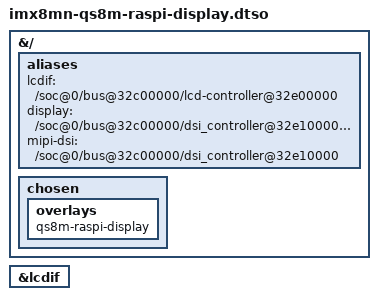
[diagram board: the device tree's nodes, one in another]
// SPDX-License-Identifier: (GPL-2.0 OR MIT)
/*
 * Copyright 2022 Lothar Waßmann <LW@KARO-electronics.de>
 *
 */

/dts-v1/;

/plugin/;

#include "includes/imx8m-karo-raspi-display.dtsi"

&{/} {
	aliases {
		lcdif = "/soc@0/bus@32c00000/lcd-controller@32e00000";
		display = "/soc@0/bus@32c00000/dsi_controller@32e10000/panel@0";
		mipi-dsi = "/soc@0/bus@32c00000/dsi_controller@32e10000";
	};

	chosen {
		overlays {
			qs8m-raspi-display;
		};
	};
};

&lcdif {
	status = "okay";
};
